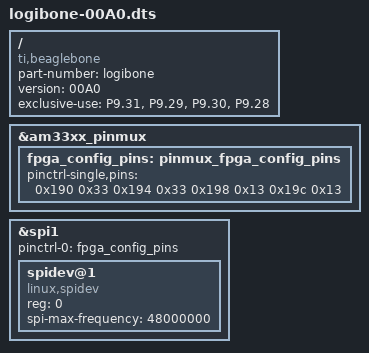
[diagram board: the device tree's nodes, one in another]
/*
Matt Venn for Arcola Energy 2016
*/

/dts-v1/;
/plugin/;

/ {
   // This determines which boards can use this DTS overlay
   compatible = "ti,beaglebone", "ti,beaglebone-green", "ti,beaglebone-black";

   // I think part-number is supposed to correspond with the filename,
   // so we'd save this as "prudaq-00A0.dts".
   part-number = "logibone";

   // This always seems to be 00A0, and all the .dtbo files in /lib/firmware
   // seem to be named foo-00A0.dtbo, but then are loaded without that suffix by
   // echo foo > /sys/devices/bone_capemgr.?/slots
   version = "00A0";

   exclusive-use =
         // These pins will be configured as inputs to PRU1
         "P9.31", "P9.29", "P9.30", "P9.28"; 

   fragment@0 {
      target = <&am33xx_pinmux>;
      __overlay__ {
	fpga_config_pins: pinmux_fpga_config_pins {
		pinctrl-single,pins = <
		/* config clk and data */
		0x190 0x33    /* P9_31 = mcasp0_aclkx.spi1_sclk                 , INPUT_PULLUP | MODE3 */
		0x194 0x33    /* P9_29 = mcasp0_fsx.spi1_d0                     , INPUT_PULLUP  | MODE3 */
		0x198 0x13    /* P9_30 = mcasp0_axr0.spi1_d1                     , OUTPUT_PULLUP | MODE3 */
		0x19c 0x13    /* P9_28 = mcasp0_ahclkr.spi1_cs0                 , OUTPUT_PULLUP | MODE3 */

		>;
          };
      };
   };

  // spi for logibone fpga programming
  fragment@1 {
        target = <&spi1>;
        __overlay__ {

            #address-cells     = <1>;
            #size-cells     = <0>;
            status            = "okay";
            pinctrl-names    = "default";
            pinctrl-0        = <&fpga_config_pins>;

            spidev@1{
                compatible           = "linux,spidev";
                reg               = <0>;
                spi-max-frequency = <48000000>;
            };
        };

    };

};
